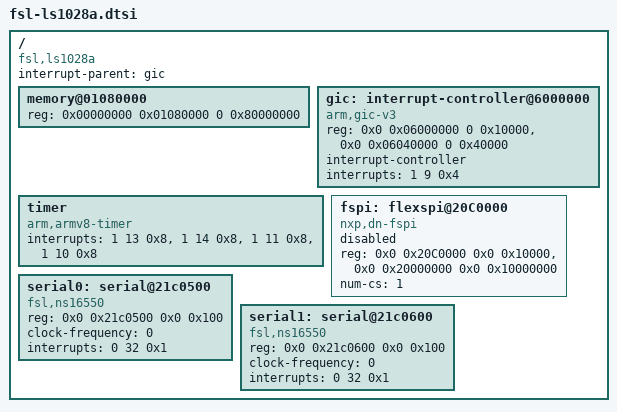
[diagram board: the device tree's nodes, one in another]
/*
 * NXP ls1028a SOC common device tree source
 *
 * Copyright 2018-2019 NXP
 *
 * SPDX-License-Identifier:	GPL-2.0+
 */

/ {
	compatible = "fsl,ls1028a";
	interrupt-parent = <&gic>;
	#address-cells = <2>;
	#size-cells = <2>;

	memory@01080000 {
		device_type = "memory";
		reg = <0x00000000 0x01080000 0 0x80000000>;
		      /* DRAM space - 1, size : 2 GB DRAM */
	};

	gic: interrupt-controller@6000000 {
		compatible = "arm,gic-v3";
		reg = <0x0 0x06000000 0 0x10000>, /* GIC Dist */
			  <0x0 0x06040000 0 0x40000>;
		#interrupt-cells = <3>;
		interrupt-controller;
		interrupts = <1 9 0x4>;
	};	

	timer {
		compatible = "arm,armv8-timer";
		interrupts = <1 13 0x8>, /* Physical Secure PPI, active-low */
			     <1 14 0x8>, /* Physical Non-Secure PPI, active-low */
			     <1 11 0x8>, /* Virtual PPI, active-low */
			     <1 10 0x8>; /* Hypervisor PPI, active-low */
	};

	fspi: flexspi@20C0000 {
		compatible = "nxp,dn-fspi";
		#address-cells = <1>;
		#size-cells = <0>;
		reg = <0x0 0x20C0000 0x0 0x10000>,
		       <0x0 0x20000000 0x0 0x10000000>; /*64MB flash*/
                               /* <0x0 0x20000000 0x0 0x4000000>;*/ /*How to incoperate 512M here*/
		reg-names = "FSPI", "FSPI-memory";
		num-cs = <1>;
		status = "disabled";
       };

	serial0: serial@21c0500 {
		device_type = "serial";
		compatible = "fsl,ns16550", "ns16550a";
		reg = <0x0 0x21c0500 0x0 0x100>;
		clock-frequency = <0>;	/* Updated by bootloader */
		interrupts = <0 32 0x1>; /* edge triggered */
	};

	serial1: serial@21c0600 {
		device_type = "serial";
		compatible = "fsl,ns16550", "ns16550a";
		reg = <0x0 0x21c0600 0x0 0x100>;
		clock-frequency = <0>; 	/* Updated by bootloader */
		interrupts = <0 32 0x1>; /* edge triggered */
	};
};
